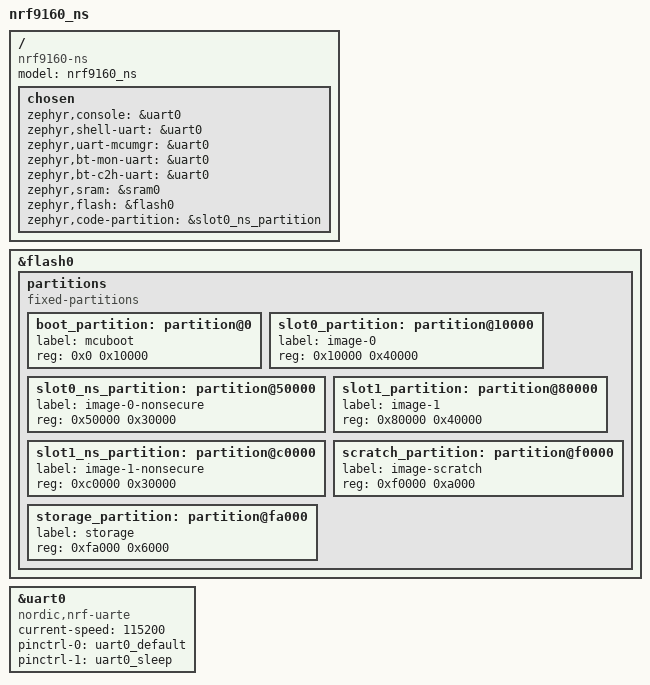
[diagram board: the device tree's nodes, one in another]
// Copyright (c) 2024 Nordic Semiconductor ASA
// SPDX-License-Identifier: Apache-2.0

/dts-v1/;
#include <nordic/nrf9160ns_sica.dtsi>
#include "nrf9160_ns-pinctrl.dtsi"


/ {
	model = "nrf9160_ns";
	compatible = "nrf9160-ns";

	chosen {
		zephyr,console = &uart0;
		zephyr,shell-uart = &uart0;
		zephyr,uart-mcumgr = &uart0;
		zephyr,bt-mon-uart = &uart0;
		zephyr,bt-c2h-uart = &uart0;
		zephyr,sram = &sram0;
		zephyr,flash = &flash0;
		zephyr,code-partition = &slot0_ns_partition;
	};
};

&flash0 {
	partitions {
		compatible = "fixed-partitions";
		#address-cells = <1>;
		#size-cells = <1>;

		boot_partition: partition@0 {
			label = "mcuboot";
			reg = <0x0 0x10000>;
		};
		slot0_partition: partition@10000 {
			label = "image-0";
			reg = <0x10000 0x40000>;
		};
		slot0_ns_partition: partition@50000 {
			label = "image-0-nonsecure";
			reg = <0x50000 0x30000>;
		};
		slot1_partition: partition@80000 {
			label = "image-1";
			reg = <0x80000 0x40000>;
		};
		slot1_ns_partition: partition@c0000 {
			label = "image-1-nonsecure";
			reg = <0xc0000 0x30000>;
		};
		scratch_partition: partition@f0000 {
			label = "image-scratch";
			reg = <0xf0000 0xa000>;
		};
		storage_partition: partition@fa000 {
			label = "storage";
			reg = <0xfa000 0x6000>;
		};
	};
};

&uart0 {
	compatible = "nordic,nrf-uarte";
	status = "okay";
	current-speed = <115200>;
	pinctrl-0 = <&uart0_default>;
	pinctrl-1 = <&uart0_sleep>;
	pinctrl-names = "default", "sleep";
};



